# alb32r003x register map
Vendor: ALB; Series: ALB RT SoC
CPU: ALB XF, little endian
Registers are 32-bit, access not given, reset 0x0 unless marked. A register's access mark holds for its fields unless they carry their own. Offsets are from the block's base; [hi:lo] are bit positions; {n}, {i} and the like mark numbered series; 'fields as' and 'values as' point back to an identical list.

## XFLASHC — XFLASH control
Base 0x23008000
0x04 KEYR ro — KEYR: Flash unlock-key register for secure register write access
  [31:0] FKEYR[31:0] — The key used to unlock the FLASH_CR register must be written in the following order before the FLASH_CR register can be written to initiate erasure and write operations
    0x45670123=KEY1; 0xCDEF89AB=KEY2
0x08 OPTKEYR ro — OPTKEYR: Option-byte unlock-key register for secure configuration updates
  [31:0] OPTKEYR[31:0] — To unlock the FLASH_OPTCR register, the optkey value must be written in the following order before writing to the FLASH_OPTCR register.
    0x8192A3B=KEY1; 0x4C5D6E7F=KEY2
0x0C SR ro — SR: Flash status register indicating busy, error and protection states
  [16] BSY — Flash is busy.
    0=INACTIVE (No Flash erase or write operations are currently being performed); 1=ACTIVE (The Flash erase and write operation is currently being executed)
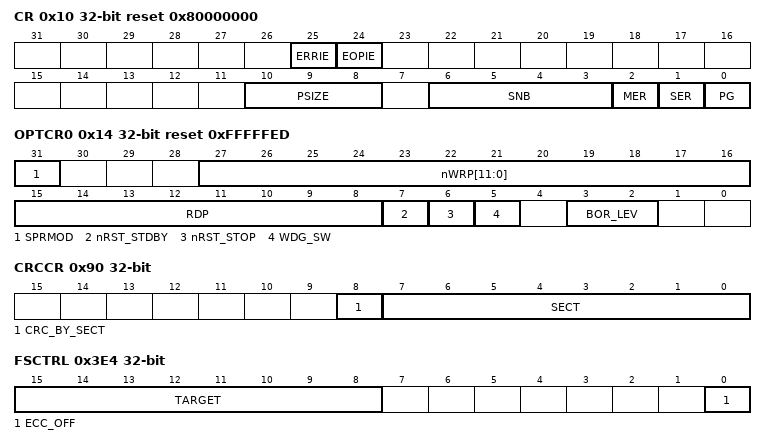
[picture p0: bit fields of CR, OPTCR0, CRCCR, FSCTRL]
0x10 CR rw reset 0x80000000 — CR: Flash control register for program/erase commands and global settings
  [25] ERRIE — Incorrect interrupt enable
    0=DISABLED (Error interrupts are prohibited); 1=ENABLED (Enable an error interrupt)
  [24] EOPIE — Interrupt the enable at the end of the operation
    0=DISABLED (Interruption is prohibited); 1=ENABLED (Enabling causes an interruption)
  [10:8] PSIZE — Programming size
    0=x8 Programming; 1=x16 Programming; 2=x32 Programming; 3=x64 Programming; 4=x128 Programming
  [6:3] SNB — Sector number
    {v}=Sector {v} (v=0..11)
  [2] MER — Whole-piece erasing enable
    1=ENABLED (Enable the entire FlashMAIN area to be erased); 0=DISABLED (Invalid)
  [1] SER — Sector erasure
    1=ENABLED (Enable sector erasure); 0=DISABLED (Invalid)
  [0] PG — Programming
    1=ENABLED (Enable Flash programming); 0=DISABLED (Invalid)
0x14 OPTCR0 rw reset 0xFFFFFED — OPTCR0: Option-byte control register 0 for user, read-out and write-protection options
  [31] SPRMOD — Selection of nWPRi bit protection mode
    0=DISABLED (Prohibit PCROP. The nWPRi bit is used for sector i write protection); 1=ENABLED (Enable PCROP, and the nWPRi bit is used for sector iPCROP protection.)
  [27:16] nWRP[11:0] — Write protection for sectors 11 to 0
    0=ACTIVE(0) (Activate the write protection of sector i(If SPRMOD is reset)); 1=INACTIVE(0) (Write protection for unactivated sector i(If SPRMOD is reset)); 0=ACTIVE(1) (PCROP protection for unactivated sector i(If SPRMOD is set to 1)); 1=INACTIVE(1) (Activate the PCROP protection of sector i(If SPRMOD is set to 1))
  [15:8] RDP — Read protection
    170=Level 0 (Read protection not activated); 204=Level 2 (Activate the chip read protection); 85=Level 1 (Activate the memory read protection)
  [7] nRST_STDBY — A reset event occurs when entering standby mode
    0=YES (A reset occurs when entering standby mode.); 1=NO (No reset occurs)
  [6] nRST_STOP — A reset event occurs when entering the stop mode
    0=YES (A reset occurs when entering the shutdown mode); 1=NO (No reset occurs)
  [5] WDG_SW — Hardware or software watchdog Settings
    0=HW (Hardware independent watchdog); 1=SW (software independent watchdog)
  [3:2] BOR_LEV — BOR reset level
    0=VBOR3 (Under-voltage threshold level 3); 1=VBOR2 (Under-voltage threshold level 2); 2=VBOR1 (Under-voltage threshold level 1); 3=CLOSE (When BOR is turned off, apply the POR/PDR reset threshold voltage)
0x18 OPTCR1 rw reset 0xFFFF — OPTCR1: Option-byte control register 1 for user, read-out and write-protection options
  [11:0] nWRP[SECT_NUM_1:12] — Write protection for sectors 27 to 12
    values as OPTCR0.nWRP[11:0]
0x20 PECFGR — PECFGR: Peripheral configuration register enabling CRC engine clock and mode selection
0x24 PEKEYR — PEKEYR: Peripheral unlock-key register for secure write access to CRC registers
0x90 CRCCR rw — CRCCR: CRC control register defining polynomial, bit order and data inversion settings
  [8] CRC_BY_SECT — CRC calculation mode selection
    0=ADDRESS (Address interval definition pattern); 1=SECTOR (Sector definition pattern.)
  [7:0] SECT — The sectors read during the CRC calculation of the data
    {v}=Sector {v} (v=0..27)
0x94 CRCSAR — CRCSAR: CRC source address register pointing to memory region for checksum calculation
0x98 CRCEAR — CRCEAR: CRC end address register marking the upper bound of the checksum memory range
0x9C CRCDR — CRCDR: CRC data-result register holding the computed checksum value
0x380 CKDIVR reset 0x2 — CKDIVR: Clock-divider register setting the CRC engine clock prescaler
0x384 SAMPLE_DELAY rw — SAMPLE_DELAY: Sampling-delay register adjusting external-flash read-latency compensation
  [16] SE — Sampling delay counting starts at the edge of the clock
    1=DOWN (Start counting the sampling delay from the falling edge of the clock); 0=UP (Technical sampling delay starts from the rising edge of the clock.)
0x3E0 FSLOCK — FSLOCK: Flash-security lock register controlling read-out and debug-access protection
0x3E4 FSCTRL rw — FSCTRL: Flash-sequence control register initiating program/erase operations and status polling
  [15:8] TARGET — The goal of functional safety
    0=INTERFACE; 1=MEMORY
  [0] ECC_OFF — ECC check switch
    1=DISABLED (Disable ECC check); 0=ENABLED (Enable ECC check)
0x3E8 FSDATA — FSDATA: Flash-sector data register for temporary storage during program/verify operations
0x3EC FSINFO — FSINFO: Flash-sector information register providing erase-state and protection status
0x3F8 PARAM1 — PARAM1: Device-parameter register 1 supplying silicon-specific timing and geometry constants
0x3FC REV — REV: Revision register returning the current IP core version and metal-layer revision
